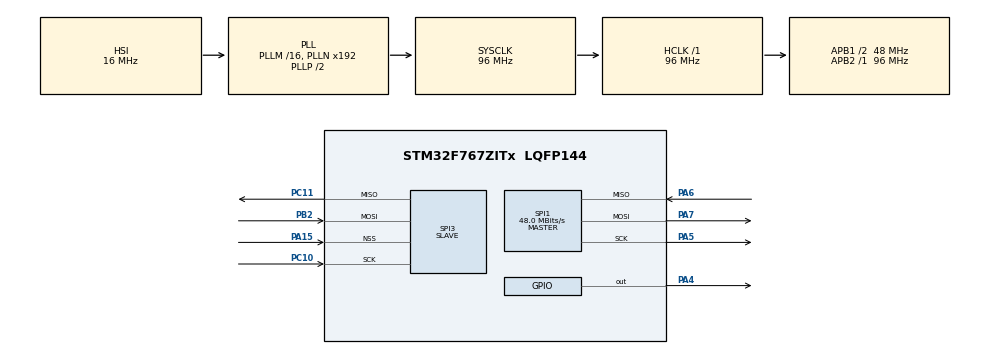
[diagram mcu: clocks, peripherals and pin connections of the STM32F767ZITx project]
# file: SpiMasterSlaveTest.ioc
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Mcu.Family=STM32F7
Mcu.Name=STM32F767ZITx
Mcu.Package=LQFP144
NVIC.PriorityGroup=NVIC_PRIORITYGROUP_4
PA15.Mode=NSS_Signal_Hard_Input
PA15.Signal=SPI3_NSS
PA4.GPIO_PuPd=GPIO_PULLUP
PA4.GPIO_Speed=GPIO_SPEED_FREQ_VERY_HIGH
PA4.PinState=GPIO_PIN_RESET
PA4.Signal=GPIO_Output
PA5.Mode=Full_Duplex_Master
PA5.Signal=SPI1_SCK
PA6.Mode=Full_Duplex_Master
PA6.Signal=SPI1_MISO
PA7.Mode=Full_Duplex_Master
PA7.Signal=SPI1_MOSI
PB2.Mode=Full_Duplex_Slave
PB2.Signal=SPI3_MOSI
PC10.Mode=Full_Duplex_Slave
PC10.Signal=SPI3_SCK
PC11.Mode=Full_Duplex_Slave
PC11.Signal=SPI3_MISO
ProjectManager.HeapSize=0x200
ProjectManager.StackSize=0x400
ProjectManager.TargetToolchain=TrueSTUDIO
RCC.AHBFreq_Value=96000000
RCC.APB1CLKDivider=RCC_HCLK_DIV2
RCC.APB1Freq_Value=48000000
RCC.APB1TimFreq_Value=96000000
RCC.APB2Freq_Value=96000000
RCC.APB2TimFreq_Value=96000000
RCC.CortexFreq_Value=96000000
RCC.HCLKFreq_Value=96000000
RCC.HSE_VALUE=25000000
RCC.HSI_VALUE=16000000
RCC.LSE_VALUE=32768
RCC.SYSCLKFreq_VALUE=96000000
RCC.SYSCLKSource=RCC_SYSCLKSOURCE_PLLCLK
RCC.USBFreq_Value=96000000
RCC.VCOOutputFreq_Value=192000000
SPI1.CalculateBaudRate=48.0 MBits/s
SPI1.DataSize=SPI_DATASIZE_8BIT
SPI1.Direction=SPI_DIRECTION_2LINES
SPI1.Mode=SPI_MODE_MASTER
SPI1.VirtualType=VM_MASTER
SPI3.DataSize=SPI_DATASIZE_8BIT
SPI3.Direction=SPI_DIRECTION_2LINES
SPI3.Mode=SPI_MODE_SLAVE
SPI3.VirtualNSS=VM_NSSHARD
SPI3.VirtualType=VM_SLAVE
board=SpiMasterSlaveTest

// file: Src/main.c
/**
  ******************************************************************************
  * @file           : main.c
  * @brief          : Main program body
  ******************************************************************************
  ** This notice applies to any and all portions of this file
  * that are not between comment pairs USER CODE BEGIN and
  * USER CODE END. Other portions of this file, whether
  * inserted by the user or by software development tools
  * are owned by their respective copyright owners.
  *
  * COPYRIGHT(c) 2018 STMicroelectronics
  *
  * Redistribution and use in source and binary forms, with or without modification,
  * are permitted provided that the following conditions are met:
  *   1. Redistributions of source code must retain the above copyright notice,
  *      this list of conditions and the following disclaimer.
  *   2. Redistributions in binary form must reproduce the above copyright notice,
  *      this list of conditions and the following disclaimer in the documentation
  *      and/or other materials provided with the distribution.
  *   3. Neither the name of STMicroelectronics nor the names of its contributors
  *      may be used to endorse or promote products derived from this software
  *      without specific prior written permission.
  *
  * THIS SOFTWARE IS PROVIDED BY THE COPYRIGHT HOLDERS AND CONTRIBUTORS "AS IS"
  * AND ANY EXPRESS OR IMPLIED WARRANTIES, INCLUDING, BUT NOT LIMITED TO, THE
  * IMPLIED WARRANTIES OF MERCHANTABILITY AND FITNESS FOR A PARTICULAR PURPOSE ARE
  * DISCLAIMED. IN NO EVENT SHALL THE COPYRIGHT HOLDER OR CONTRIBUTORS BE LIABLE
  * FOR ANY DIRECT, INDIRECT, INCIDENTAL, SPECIAL, EXEMPLARY, OR CONSEQUENTIAL
  * DAMAGES (INCLUDING, BUT NOT LIMITED TO, PROCUREMENT OF SUBSTITUTE GOODS OR
  * SERVICES; LOSS OF USE, DATA, OR PROFITS; OR BUSINESS INTERRUPTION) HOWEVER
  * CAUSED AND ON ANY THEORY OF LIABILITY, WHETHER IN CONTRACT, STRICT LIABILITY,
  * OR TORT (INCLUDING NEGLIGENCE OR OTHERWISE) ARISING IN ANY WAY OUT OF THE USE
  * OF THIS SOFTWARE, EVEN IF ADVISED OF THE POSSIBILITY OF SUCH DAMAGE.
  *
  ******************************************************************************
  */
#include "main.h"
#include "stm32f7xx_hal.h"
#include "COBS.h"
#include "protocol.h"
#include <stdint.h>

SPI_HandleTypeDef hspi1;
SPI_HandleTypeDef hspi3;

/* USER CODE BEGIN PV */
/* Private variables ---------------------------------------------------------*/

/* USER CODE END PV */

void SystemClock_Config(void);
static void MX_GPIO_Init(void);
static void MX_SPI1_Init(void);
static void MX_SPI3_Init(void);

/* USER CODE BEGIN PFP */
/* Private function prototypes -----------------------------------------------*/

/* USER CODE END PFP */

int main(void)
{

  /* MCU Configuration----------------------------------------------------------*/

  /* Reset of all peripherals, Initializes the Flash interface and the Systick. */
  HAL_Init();

  /* Configure the system clock */
  SystemClock_Config();

  /* Initialize all configured peripherals */
  MX_GPIO_Init();
  MX_SPI1_Init();
  MX_SPI3_Init();

  /* Infinite loop */
  /* USER CODE BEGIN WHILE */
  char state = 0;

  uint8_t input_slave[100];
  uint8_t output_slave[100];//Maximum Buffer size

  uint8_t COBS_len = 0;

  protocol_u protocolstream;
  while (1)
	  while (1)
	   {
	 		  input_slave[0] = 0x00; // Default Values
	 		  input_slave[1] = 0x00; // Default Values
	 		  input_slave[2] = 0xFF; // Default Values
	 		  input_slave[3] = 0xFF; // Default Values
	 		  input_slave[4] = 0xFF; // Default Values
	 		  input_slave[5] = 0xFF; // Default Values
	 		  input_slave[6] = 0xFF; // Default Values
	 		  input_slave[7] = 0xFF; // Default Values
	 		  input_slave[8] = 0xFF; // Default Values
	 		  input_slave[9] = 0xFF; // Default Values

	 		  char error_OR = 0; //Error Overrun

	 		  volatile uint32_t errors_in_transmission = 0; //incorrect Bytes
	 		  volatile uint32_t successful_transmissions = 0; //100% correct transfers
	 		  volatile uint32_t unsuccessful_transmissions = 0; //Not 100% correct transfers

	 		  while(1)
	 		  {

	 			  for(int i = 0; i < 100; i++)
	 			  {
	 				  output_slave[i] = i; //To be transmitted
	 				  input_slave[i] = 0; //Default Value
	 			  }
	 			  //CLEAN FIFO
	 			  HAL_SPI_Receive(&hspi3, input_slave, 4, 0xFF);
	 			  //Synchronize (Two - Way - Handshake)
	 			  char offset = 0;
	 			  while(!((input_slave[0] == 0xFE && input_slave[1] == 0xFF) || (input_slave[1] == 0xFE && input_slave[0] == 0xFF)))
	 			  {
	 				  if(offset)
	 					  offset = 0;
	 				  else
	 					  offset = 1;
	 				  // waing for Handshake
	 				  HAL_SPI_Receive(&hspi3, input_slave + offset, 1, 0xFFFF);
	 			  }

	 			  //Send ACK
	 			  HAL_SPI_Transmit(&hspi3, output_slave, 2, 0xFFF);

	 			  //--- Should be synchronized now! ---

	 			  //Sending the 100Byte Package now!
	 			  HAL_SPI_TransmitReceive(&hspi3, output_slave, input_slave, 100, 0xFF);

	 			  //--- Check Received Bytes---
	 			  char flag_begin_not_found = 0;
	 			  if(input_slave[0] != 100)
	 					  flag_begin_not_found = 1;

	 			  //Check the received Data
	 			  char error_detected = 0; //Error detected in this transmission?
	 			  for(int i = 0; i < 100; i++)
	 			  {
	 				  if(!(input_slave[(i)%100] == i+100))
	 				  {
	 					  if(errors_in_transmission >= (1<<31))
	 						  error_OR = 1;
	 					  errors_in_transmission++;
	 					  error_detected = 1;
	 				  }
	 			  }

	 			  if(error_detected == 0)
	 				  successful_transmissions++;
	 			  else
	 				  unsuccessful_transmissions++;
	 			  /*
	 			  HAL_SPI_TransmitReceive(&hspi3, output_slave, input_slave, 4, 0xFF);
	 			  HAL_SPI_Receive(&hspi3, input_slave, 1, 0xFF);
	 			  HAL_SPI_Receive(&hspi3, input_slave, 4, 0xFF);
	 			  HAL_SPI_Transmit(&hspi3, output_slave, 1, 0xFF);
	 			  HAL_SPI_Transmit(&hspi3, output_slave, 4, 0xFF); */
	 		  }
	 	  }
  /* USER CODE END 3 */

}

void SystemClock_Config(void)
{

  RCC_OscInitTypeDef RCC_OscInitStruct;
  RCC_ClkInitTypeDef RCC_ClkInitStruct;

    /**Configure the main internal regulator output voltage
    */
  __HAL_RCC_PWR_CLK_ENABLE();

  __HAL_PWR_VOLTAGESCALING_CONFIG(PWR_REGULATOR_VOLTAGE_SCALE3);

    /**Initializes the CPU, AHB and APB busses clocks
    */
  RCC_OscInitStruct.OscillatorType = RCC_OSCILLATORTYPE_HSI;
  RCC_OscInitStruct.HSIState = RCC_HSI_ON;
  RCC_OscInitStruct.HSICalibrationValue = 16;
  RCC_OscInitStruct.PLL.PLLState = RCC_PLL_ON;
  RCC_OscInitStruct.PLL.PLLSource = RCC_PLLSOURCE_HSI;
  RCC_OscInitStruct.PLL.PLLM = 16;
  RCC_OscInitStruct.PLL.PLLN = 192;
  RCC_OscInitStruct.PLL.PLLP = RCC_PLLP_DIV2;
  RCC_OscInitStruct.PLL.PLLQ = 2;
  if (HAL_RCC_OscConfig(&RCC_OscInitStruct) != HAL_OK)
  {
    _Error_Handler(__FILE__, __LINE__);
  }

    /**Activate the Over-Drive mode
    */
  if (HAL_PWREx_EnableOverDrive() != HAL_OK)
  {
    _Error_Handler(__FILE__, __LINE__);
  }

    /**Initializes the CPU, AHB and APB busses clocks
    */
  RCC_ClkInitStruct.ClockType = RCC_CLOCKTYPE_HCLK|RCC_CLOCKTYPE_SYSCLK
                              |RCC_CLOCKTYPE_PCLK1|RCC_CLOCKTYPE_PCLK2;
  RCC_ClkInitStruct.SYSCLKSource = RCC_SYSCLKSOURCE_PLLCLK;
  RCC_ClkInitStruct.AHBCLKDivider = RCC_SYSCLK_DIV1;
  RCC_ClkInitStruct.APB1CLKDivider = RCC_HCLK_DIV2;
  RCC_ClkInitStruct.APB2CLKDivider = RCC_HCLK_DIV1;

  if (HAL_RCC_ClockConfig(&RCC_ClkInitStruct, FLASH_LATENCY_3) != HAL_OK)
  {
    _Error_Handler(__FILE__, __LINE__);
  }

    /**Configure the Systick interrupt time
    */
  HAL_SYSTICK_Config(HAL_RCC_GetHCLKFreq()/1000);

    /**Configure the Systick
    */
  HAL_SYSTICK_CLKSourceConfig(SYSTICK_CLKSOURCE_HCLK);

  /* SysTick_IRQn interrupt configuration */
  HAL_NVIC_SetPriority(SysTick_IRQn, 0, 0);
}

/* SPI1 init function */
static void MX_SPI1_Init(void)
{

  /* SPI1 parameter configuration*/
  hspi1.Instance = SPI1;
  hspi1.Init.Mode = SPI_MODE_MASTER;
  hspi1.Init.Direction = SPI_DIRECTION_2LINES;
  hspi1.Init.DataSize = SPI_DATASIZE_8BIT;
  hspi1.Init.CLKPolarity = SPI_POLARITY_LOW;
  hspi1.Init.CLKPhase = SPI_PHASE_1EDGE;
  hspi1.Init.NSS = SPI_NSS_SOFT;
  hspi1.Init.BaudRatePrescaler = SPI_BAUDRATEPRESCALER_2;
  hspi1.Init.FirstBit = SPI_FIRSTBIT_MSB;
  hspi1.Init.TIMode = SPI_TIMODE_DISABLE;
  hspi1.Init.CRCCalculation = SPI_CRCCALCULATION_DISABLE;
  hspi1.Init.CRCPolynomial = 7;
  hspi1.Init.CRCLength = SPI_CRC_LENGTH_DATASIZE;
  hspi1.Init.NSSPMode = SPI_NSS_PULSE_ENABLE;
  if (HAL_SPI_Init(&hspi1) != HAL_OK)
  {
    _Error_Handler(__FILE__, __LINE__);
  }

}

/* SPI3 init function */
static void MX_SPI3_Init(void)
{

  /* SPI3 parameter configuration*/
  hspi3.Instance = SPI3;
  hspi3.Init.Mode = SPI_MODE_SLAVE;
  hspi3.Init.Direction = SPI_DIRECTION_2LINES;
  hspi3.Init.DataSize = SPI_DATASIZE_8BIT;
  hspi3.Init.CLKPolarity = SPI_POLARITY_LOW;
  hspi3.Init.CLKPhase = SPI_PHASE_1EDGE;
  hspi3.Init.NSS = SPI_NSS_HARD_INPUT;
  hspi3.Init.FirstBit = SPI_FIRSTBIT_MSB;
  hspi3.Init.TIMode = SPI_TIMODE_DISABLE;
  hspi3.Init.CRCCalculation = SPI_CRCCALCULATION_DISABLE;
  hspi3.Init.CRCPolynomial = 7;
  hspi3.Init.CRCLength = SPI_CRC_LENGTH_DATASIZE;
  hspi3.Init.NSSPMode = SPI_NSS_PULSE_DISABLE;
  if (HAL_SPI_Init(&hspi3) != HAL_OK)
  {
    _Error_Handler(__FILE__, __LINE__);
  }

}

/** Configure pins as
        * Analog
        * Input
        * Output
        * EVENT_OUT
        * EXTI
*/
static void MX_GPIO_Init(void)
{

  GPIO_InitTypeDef GPIO_InitStruct;

  /* GPIO Ports Clock Enable */
  __HAL_RCC_GPIOA_CLK_ENABLE();
  __HAL_RCC_GPIOB_CLK_ENABLE();
  __HAL_RCC_GPIOC_CLK_ENABLE();

  /*Configure GPIO pin Output Level */
  HAL_GPIO_WritePin(GPIOA, GPIO_PIN_4, GPIO_PIN_RESET);

  /*Configure GPIO pin : PA4 */
  GPIO_InitStruct.Pin = GPIO_PIN_4;
  GPIO_InitStruct.Mode = GPIO_MODE_OUTPUT_PP;
  GPIO_InitStruct.Pull = GPIO_PULLUP;
  GPIO_InitStruct.Speed = GPIO_SPEED_FREQ_VERY_HIGH;
  HAL_GPIO_Init(GPIOA, &GPIO_InitStruct);

}

/* USER CODE BEGIN 4 */

/** Check for expected result of received Data.
 * @return Array as expected (0: false)
*/
char checkReceivedData(uint8_t *arr)
{
	for(int i = 0; i < 4; i++)
	{
		if(arr[i] != 2*(i+1))
			return 0;
	}
	return 1;
}
/* USER CODE END 4 */

void _Error_Handler(char *file, int line)
{
  while(1)
  {
  }
}

/************************ (C) COPYRIGHT STMicroelectronics *****END OF FILE****/
